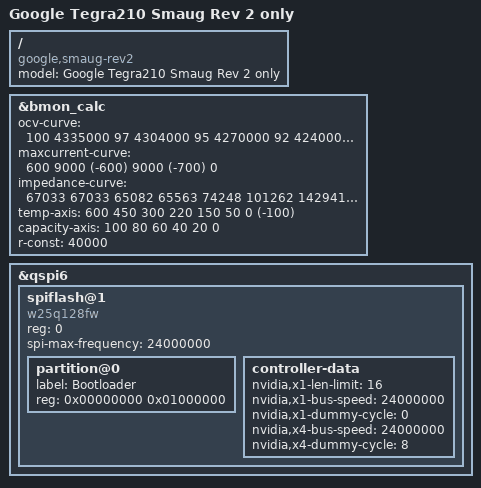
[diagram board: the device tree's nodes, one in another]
/dts-v1/;

#include "tegra210-smaug.dtsi"

/ {
	model = "Google Tegra210 Smaug Rev 2 only";
	compatible = "google,smaug-rev2", "google,smaug", "nvidia,tegra210";
};

&bmon_calc {
	ocv-curve = <
		100	4335000
		97	4304000
		95	4270000
		92	4240000
		90	4210000
		87	4181000
		85	4153000
		82	4124000
		79	4098000
		77	4071000
		74	4046000
		72	4023000
		69	3999000
		67	3979000
		64	3960000
		62	3938000
		59	3914000
		56	3892000
		54	3871000
		51	3847000
		49	3834000
		46	3822000
		44	3811000
		41	3803000
		38	3793000
		36	3787000
		33	3780000
		31	3775000
		28	3771000
		26	3766000
		23	3752000
		21	3740000
		18	3724000
		15	3700000
		13	3686000
		10	3680000
		8	3679000
		5	3636000
		3	3484000
		0	2923000
		>;
	maxcurrent-curve = <
		600	9000
		(-600)	9000
		(-700)	0
		>;
	impedance-curve = <
		/* 60C  45C	    30C	    22C	    15C	    50C	    0C	    -10C */
		67033	67033	65082	65563	74248	101262	142941	142941	/* 100% */
		67004	67004	65118	64381	73787	100638	142065	142065	/* 80% */
		67103	67103	65371	64000	70778	90388	114825	114825	/* 60% */
		67408	67408	65894	64533	70229	87182	104433	104433	/* 40% */
		68272	68272	67117	65945	71666	89842	108942	108942	/* 20% */
		72328	72328	71869	71538	81803	95724	118174	118174	/* 0% */
		>;
	temp-axis = <600 450 300 220 150 50 0 (-100)>;
	capacity-axis = <100 80 60 40 20 0>;
	r-const = <40000>;
};

&qspi6 {
	spiflash@1 {
		#address-cells = <1>;
		#size-cells = <1>;
		compatible = "w25q128fw";
		reg = <0>;
		spi-max-frequency = <24000000>;
		partition@0 {
			label = "Bootloader";
			reg = <0x00000000 0x01000000>;
		};
		controller-data {
			nvidia,x1-len-limit = <16>;
			nvidia,x1-bus-speed = <24000000>;
			nvidia,x1-dummy-cycle = <0>;
			nvidia,x4-bus-speed = <24000000>;
			nvidia,x4-dummy-cycle = <8>;
		};
	};
};
